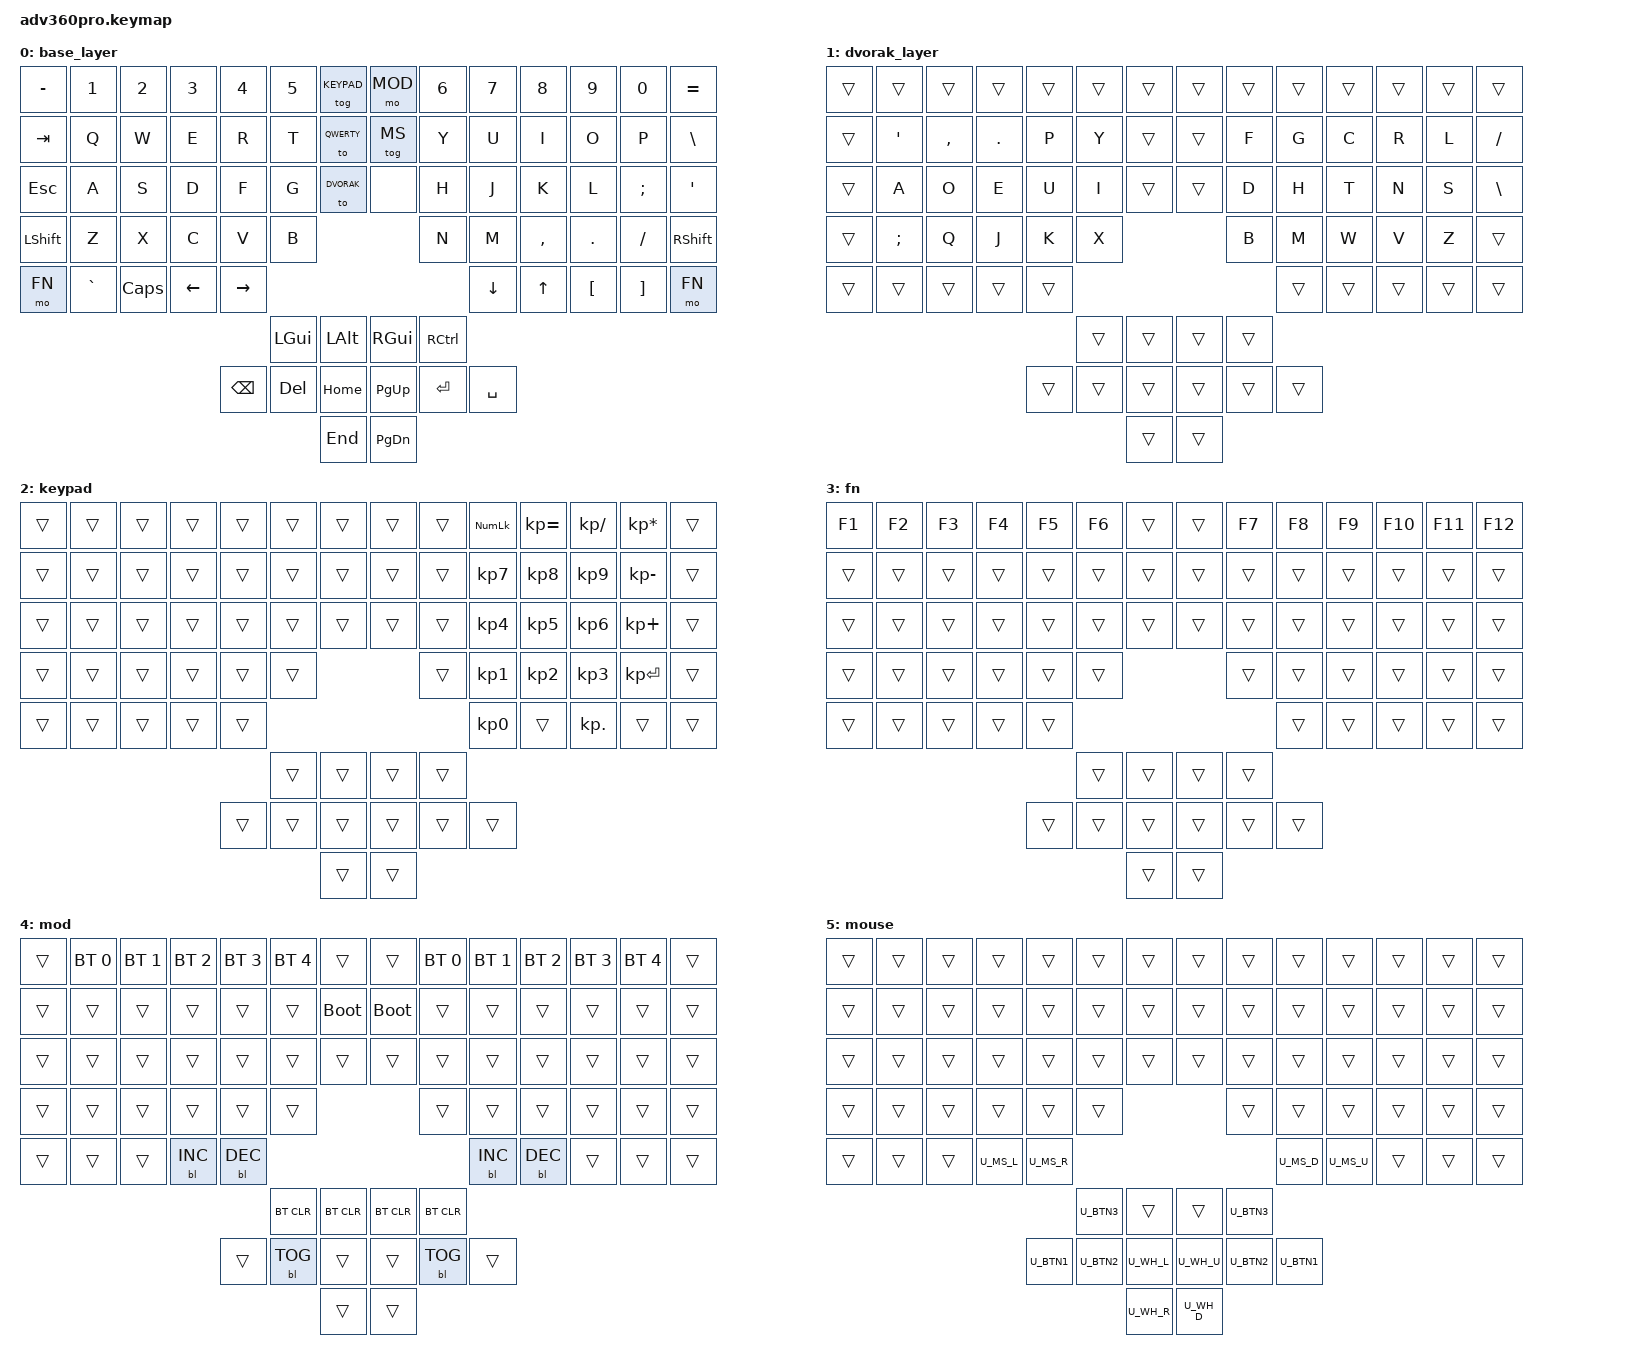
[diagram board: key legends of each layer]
#include <behaviors.dtsi>
#include <dt-bindings/zmk/keys.h>
#include <dt-bindings/zmk/bt.h>
#include <dt-bindings/zmk/outputs.h>
#include <dt-bindings/zmk/rgb.h>
#include <dt-bindings/zmk/backlight.h>

/* definitions for mouse layer */
#include "mouse.dtsi"

#define ___ &trans

#define QWERTY 0
#define DVORAK 1
#define KEYPAD 2
#define FN 3
#define MOD 4
#define MS 5

/ {
    /* remove unused keys from layout and move thumb cluster to bottom */
    chosen {
        zmk,matrix_transform = &urobs_transform;
    };

    keymap {
        compatible = "zmk,keymap";

        base_layer {
            bindings = <
                &kp MINUS &kp N1    &kp N2    &kp N3    &kp N4    &kp N5    &tog KEYPAD    &mo MOD   &kp N6    &kp N7    &kp N8    &kp N9    &kp N0    &kp EQUAL
                &kp TAB   &kp Q     &kp W     &kp E     &kp R     &kp T     &to QWERTY     &tog MS   &kp Y     &kp U     &kp I     &kp O     &kp P     &kp BSLH
                &kp ESC   &kp A     &kp S     &kp D     &kp F     &kp G     &to DVORAK     &none     &kp H     &kp J     &kp K     &kp L     &kp SEMI  &kp SQT
                &kp LSHFT &kp Z     &kp X     &kp C     &kp V     &kp B                              &kp N     &kp M     &kp COMMA &kp DOT   &kp FSLH  &kp RSHFT
                &mo FN    &kp GRAVE &kp CAPS  &kp LEFT  &kp RIGHT                                              &kp DOWN  &kp UP    &kp LBKT  &kp RBKT  &mo FN
                                                                  &kp LGUI  &kp LALT       &kp RGUI  &kp RCTRL
                                                        &kp BSPC  &kp DEL   &kp HOME       &kp PG_UP &kp ENTER &kp SPACE
                                                                            &kp END        &kp PG_DN
            >;
        };

        dvorak_layer {
            bindings = <
         
                ___       ___       ___       ___       ___       ___       ___            ___       ___       ___       ___       ___       ___       ___
                ___       &kp SQT   &kp COMMA &kp DOT   &kp P     &kp Y     ___            ___       &kp F     &kp G     &kp C     &kp R     &kp L     &kp FSLH
                ___       &kp A     &kp O     &kp E     &kp U     &kp I     ___            ___       &kp D     &kp H     &kp T     &kp N     &kp S     &kp BSLH
                ___       &kp SEMI  &kp Q     &kp J     &kp K     &kp X                              &kp B     &kp M     &kp W     &kp V     &kp Z     ___
                ___       ___       ___       ___       ___                                                    ___       ___       ___       ___       ___
                                                                  ___       ___            ___       ___
                                                        ___       ___       ___            ___       ___       ___
                                                                            ___            ___
            >;
        };

        keypad {
            bindings = <
                ___       ___       ___       ___       ___       ___       ___            ___       ___       &kp KP_NUM &kp KP_EQUAL &kp KP_DIVIDE &kp KP_MULTIPLY ___
                ___       ___       ___       ___       ___       ___       ___            ___       ___       &kp KP_N7  &kp KP_N8    &kp KP_N9     &kp KP_MINUS    ___
                ___       ___       ___       ___       ___       ___       ___            ___       ___       &kp KP_N4  &kp KP_N5    &kp KP_N6     &kp KP_PLUS     ___
                ___       ___       ___       ___       ___       ___                                ___       &kp KP_N1  &kp KP_N2    &kp KP_N3     &kp KP_ENTER    ___
                ___       ___       ___       ___       ___                                                    &kp KP_N0  ___          &kp KP_DOT    ___             ___
                                                                  ___       ___            ___       ___
                                                        ___       ___       ___            ___       ___       ___
                                                                            ___            ___
            >;
        };

        fn {
            bindings = <
                &kp F1    &kp F2    &kp F3    &kp F4    &kp F5    &kp F6    ___            ___       &kp F7    &kp F8    &kp F9    &kp F10   &kp F11   &kp F12
                ___       ___       ___       ___       ___       ___       ___            ___       ___       ___       ___       ___       ___       ___
                ___       ___       ___       ___       ___       ___       ___            ___       ___       ___       ___       ___       ___       ___
                ___       ___       ___       ___       ___       ___                                ___       ___       ___       ___       ___       ___
                ___       ___       ___       ___       ___                                                    ___       ___       ___       ___       ___
                                                                  ___       ___            ___       ___
                                                        ___       ___       ___            ___       ___       ___
                                                                            ___            ___
            >;
        };

        mod {
            bindings = <
                ___       &bt BT_SEL 0 &bt BT_SEL 1 &bt BT_SEL 2 &bt BT_SEL 3 &bt BT_SEL 4 ___              ___         &bt BT_SEL 0 &bt BT_SEL 1     &bt BT_SEL 2 &bt BT_SEL 3 &bt BT_SEL 4 ___
                ___       ___          ___          ___          ___          ___          &bootloader      &bootloader ___          ___              ___          ___          ___          ___
                ___       ___          ___          ___          ___          ___          ___              ___         ___          ___              ___          ___          ___          ___
                ___       ___          ___          ___          ___          ___                                       ___          ___              ___          ___          ___          ___
                ___       ___          ___          &bl BL_INC   &bl BL_DEC                                                          &bl BL_INC       &bl BL_DEC   ___          ___          ___
                                                                              &bt BT_CLR   &bt BT_CLR       &bt BT_CLR  &bt BT_CLR
                                                                 ___          &bl BL_TOG   ___              ___         &bl BL_TOG   ___
                                                                                           ___              ___
            >;
        };

        mouse {
            bindings = <
                ___       ___       ___       ___       ___       ___       ___            ___       ___       ___       ___       ___       ___       ___
                ___       ___       ___       ___       ___       ___       ___            ___       ___       ___       ___       ___       ___       ___
                ___       ___       ___       ___       ___       ___       ___            ___       ___       ___       ___       ___       ___       ___
                ___       ___       ___       ___       ___       ___                                ___       ___       ___       ___       ___       ___
                ___       ___       ___       U_MS_L    U_MS_R                                                 U_MS_D    U_MS_U    ___       ___       ___
                                                                  U_BTN3    ___            ___       U_BTN3
                                                        U_BTN1    U_BTN2    U_WH_L         U_WH_U    U_BTN2    U_BTN1
                                                                            U_WH_R         U_WH_D
            >;
        };

    };

};

